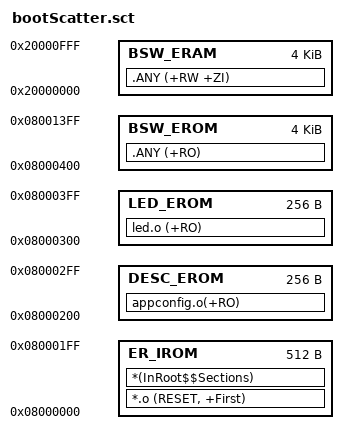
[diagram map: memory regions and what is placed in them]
;#! armcc -E
;#include "..\appConfig\appConfig.h"

; *************************************************************
; *** Scatter-Loading Description File generated by uVision ***
; *************************************************************


; *************************************************************
; *** Application INIT module *********************************
; *************************************************************
INIT_ROM    0x08000000 0x200  {    ; load region size_region
  ER_IROM   0x08000000 0x200  {  ; load address = execution address
   *.o (RESET, +First)
   *(InRoot$$Sections)
  }
}

; *************************************************************
; *** Application DESC module *********************************
; *************************************************************
DESC_LROM       0x08000200 0x100  {    ; load region size_region
    DESC_EROM   0x08000200 0x100  {  ; load address = execution address
        appconfig.o(+RO)
    }
}

; *************************************************************
; *** Application LED module *********************************
; *************************************************************
LED_LROM       0x08000300 0x100  {    ; load region size_region
    LED_EROM   0x08000300 0x100  {  ; load address = execution address
        led.o (+RO)
    }
}

; *************************************************************
; *** Application BSW module *********************************
; *************************************************************
BSW_LROM       0x08000400 0x1000  {    ; load region size_region
    BSW_EROM   0x08000400 0x1000  {  ; load address = execution address
        .ANY (+RO)
    }
    BSW_ERAM   0x20000000 0x1000 {
        .ANY (+RW +ZI)
    }
}




